# STM32H723VEH6 register map
File version: 1.0
Registers are 32-bit, access not given, reset 0x0 unless marked. A register's access mark holds for its fields unless they carry their own. Offsets are from the block's base; [hi:lo] are bit positions; {n}, {i} and the like mark numbered series.

## DCMI
Base 0x48020000
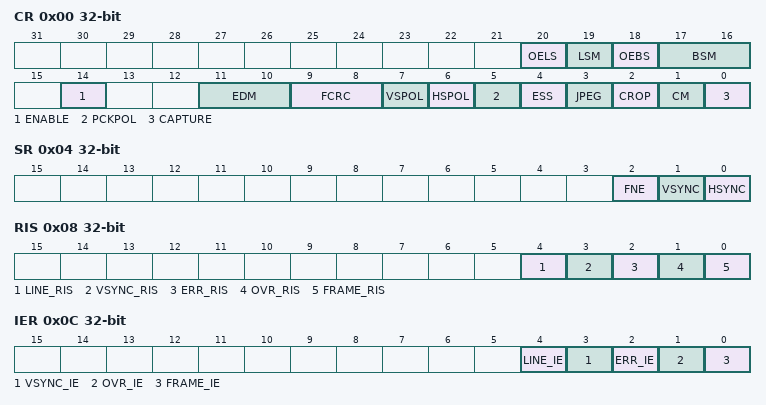
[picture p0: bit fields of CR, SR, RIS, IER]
0x00 CR
  [20] OELS, [19] LSM, [18] OEBS, [17:16] BSM, [14] ENABLE, [11:10] EDM, [9:8] FCRC, [7] VSPOL, [6] HSPOL, [5] PCKPOL, [4] ESS, [3] JPEG, [2] CROP, [1] CM, [0] CAPTURE
0x04 SR
  [2] FNE, [1] VSYNC, [0] HSYNC
0x08 RIS
  [4] LINE_RIS, [3] VSYNC_RIS, [2] ERR_RIS, [1] OVR_RIS, [0] FRAME_RIS
0x0C IER
  [4] LINE_IE, [3] VSYNC_IE, [2] ERR_IE, [1] OVR_IE, [0] FRAME_IE
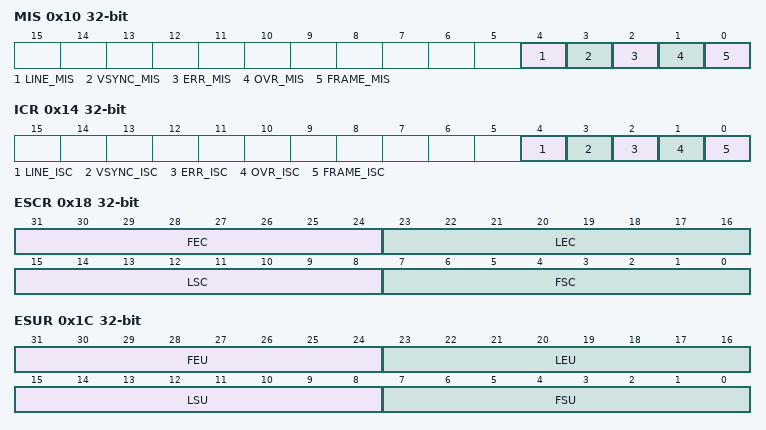
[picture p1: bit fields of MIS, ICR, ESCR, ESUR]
0x10 MIS
  [4] LINE_MIS, [3] VSYNC_MIS, [2] ERR_MIS, [1] OVR_MIS, [0] FRAME_MIS
0x14 ICR
  [4] LINE_ISC, [3] VSYNC_ISC, [2] ERR_ISC, [1] OVR_ISC, [0] FRAME_ISC
0x18 ESCR
  [31:24] FEC, [23:16] LEC, [15:8] LSC, [7:0] FSC
0x1C ESUR
  [31:24] FEU, [23:16] LEU, [15:8] LSU, [7:0] FSU
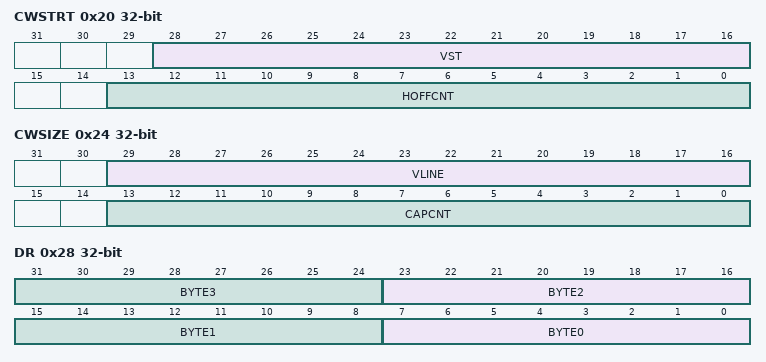
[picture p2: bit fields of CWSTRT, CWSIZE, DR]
0x20 CWSTRT
  [28:16] VST, [13:0] HOFFCNT
0x24 CWSIZE
  [29:16] VLINE, [13:0] CAPCNT
0x28 DR
  [8n+7:8n] BYTE{n} (n=0..3)

## PSSI
Base 0x48020400
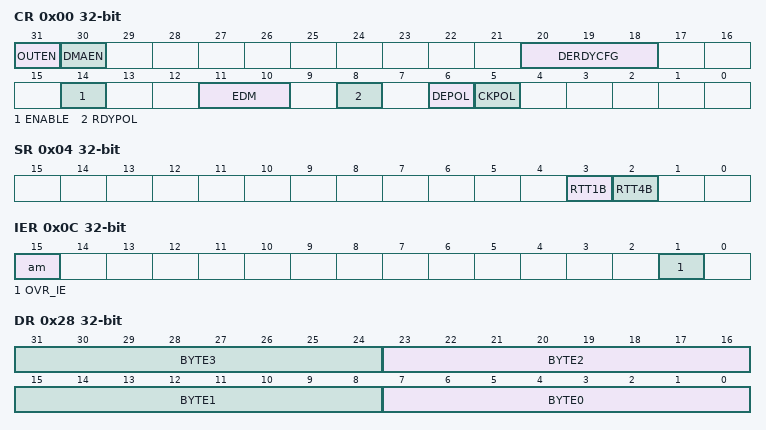
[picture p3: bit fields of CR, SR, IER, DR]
0x00 CR
  [31] OUTEN, [30] DMAEN, [20:18] DERDYCFG, [14] ENABLE, [11:10] EDM, [8] RDYPOL, [6] DEPOL, [5] CKPOL
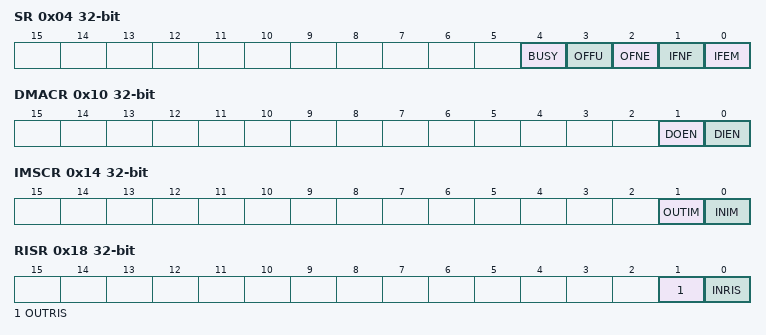
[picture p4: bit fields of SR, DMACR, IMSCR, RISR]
0x04 SR
  [3] RTT1B, [2] RTT4B
0x08 RIS
  [1] OVR_RIS
0x0C IER
  [15] am, [1] OVR_IE
0x10 MIS
  [1] OVR_MIS
0x14 ICR
  [1] OVR_ISC
0x28 DR
  [8n+7:8n] BYTE{n} (n=0..3)

## CRYPTO
Base 0x48021000
0x00 CR
  [23:20] NPBLB, [17:16] GCM_CCMPH, [15] CRYPEN, [14] FFLUSH, [9:8] KEYSIZE, [7:6] DATATYPE, [19:3] ALGOMODE, [2] ALGODIR
0x04 SR
  [4] BUSY, [3] OFFU, [2] OFNE, [1] IFNF, [0] IFEM
0x08 DIN
  [31:0] DATAIN
0x0C DOUT
  [31:0] DATAOUT
0x10 DMACR
  [1] DOEN, [0] DIEN
0x14 IMSCR
  [1] OUTIM, [0] INIM
0x18 RISR
  [1] OUTRIS, [0] INRIS
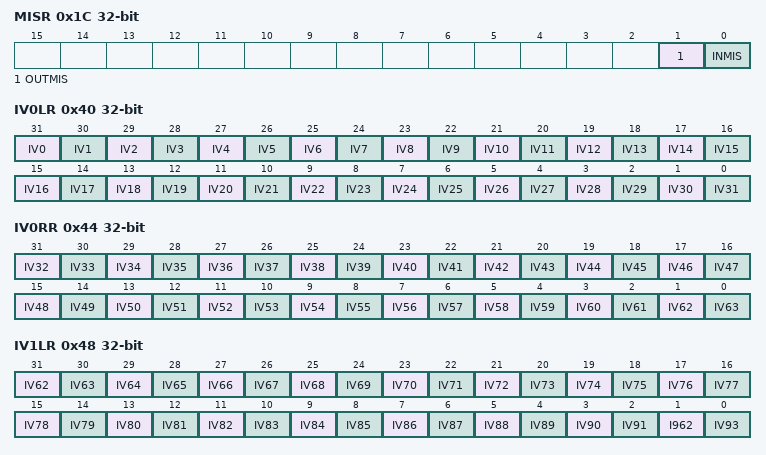
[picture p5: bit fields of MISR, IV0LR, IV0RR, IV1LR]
0x1C MISR
  [1] OUTMIS, [0] INMIS
0x20 K0LR
  [31:0] K
0x24 K0RR
  [31:0] K
0x38 K3LR
  [31:0] K
0x3C K3RR
  [31:0] K
0x40 IV0LR
  [31-n] IV{n} (n=0..31)
0x44 IV0RR
  [63-n] IV{n} (n=32..63)
0x48 IV1LR
  [93-n] IV{n} (n=62..91), [1] I962, [0] IV93
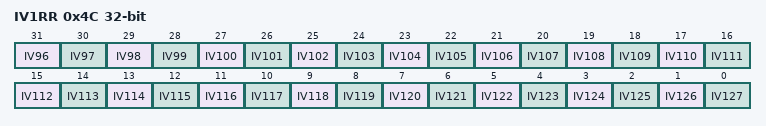
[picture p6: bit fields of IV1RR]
0x4C IV1RR
  [127-n] IV{n} (n=96..127)
{0x50+4i} CSGCMCCM{i}R (i=0..7)
  [31:0] CSGCMCCM{i}
{0x70+4i} CSGCM{i}R (i=0..7)
  [31:0] CSGCM{i}

## HASH
Base 0x48021400
0x00 CR
  [16] LKEY, [13] MDMAT, [12] DINNE, [11:8] NBW, [18:7] ALGO, [6] MODE, [5:4] DATATYPE, [3] DMAE, [2] INIT
0x04 DIN
  [31:0] DATAIN
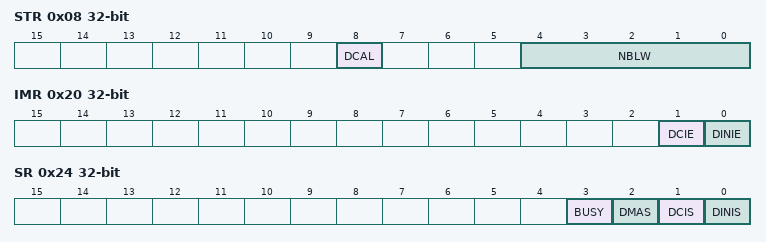
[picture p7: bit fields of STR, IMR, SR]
0x08 STR
  [8] DCAL, [4:0] NBLW
{0xC+4i} HRA{i} (i=0..4)
  [31:0] H{i}
0x20 IMR
  [1] DCIE, [0] DINIE
0x24 SR
  [3] BUSY, [2] DMAS, [1] DCIS, [0] DINIS
{0xF8+4i} CSR{i} (i=0..53)
  [31:0] CSx
{0x310+4i} HR{i} (i=0..7)
  [31:0] H{i}

## RNG
Base 0x48021800
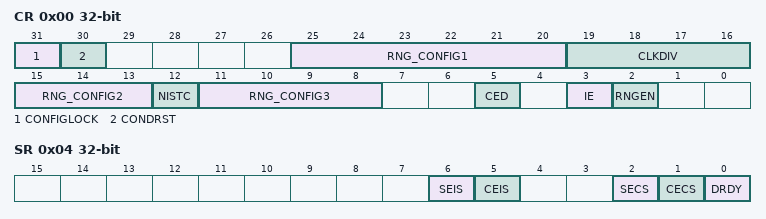
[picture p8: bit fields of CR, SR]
0x00 CR
  [31] CONFIGLOCK, [30] CONDRST, [25:20] RNG_CONFIG1, [19:16] CLKDIV, [15:13] RNG_CONFIG2, [12] NISTC, [11:8] RNG_CONFIG3, [5] CED, [3] IE, [2] RNGEN
0x04 SR
  [6] SEIS, [5] CEIS, [2] SECS, [1] CECS, [0] DRDY
0x08 DR
  [31:0] RNDATA
0x10 HTCR
  [31:0] HTCFG

## SDMMC2
Base 0x48022400
Same registers: SDMMC1 0x52007000
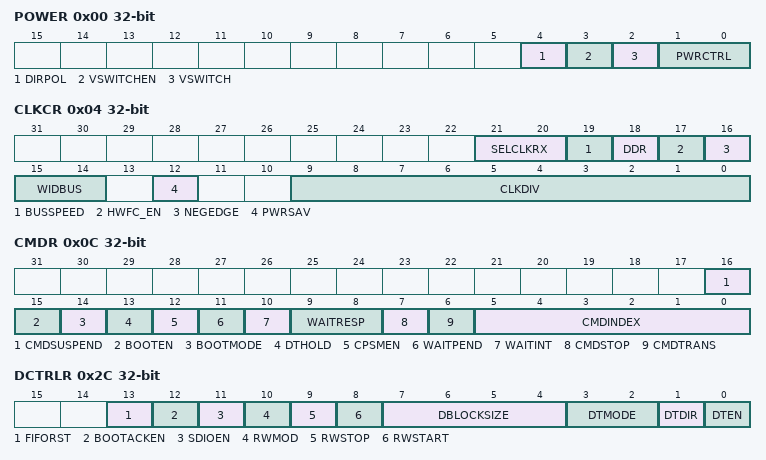
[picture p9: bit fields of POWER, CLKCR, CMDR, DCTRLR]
0x00 POWER
  [4] DIRPOL, [3] VSWITCHEN, [2] VSWITCH, [1:0] PWRCTRL
0x04 CLKCR
  [21:20] SELCLKRX, [19] BUSSPEED, [18] DDR, [17] HWFC_EN, [16] NEGEDGE, [15:14] WIDBUS, [12] PWRSAV, [9:0] CLKDIV
0x08 ARGR
  [31:0] CMDARG
0x0C CMDR
  [16] CMDSUSPEND, [15] BOOTEN, [14] BOOTMODE, [13] DTHOLD, [12] CPSMEN, [11] WAITPEND, [10] WAITINT, [9:8] WAITRESP, [7] CMDSTOP, [6] CMDTRANS, [5:0] CMDINDEX
0x10 RESPCMDR
  [5:0] RESPCMD
{0x10+4i} RESP{i}R (i=1..4)
  [31:0] CARDSTATUS
0x24 DTIMER
  [31:0] DATATIME
0x28 DLENR
  [24:0] DATALENGTH
0x2C DCTRLR
  [13] FIFORST, [12] BOOTACKEN, [11] SDIOEN, [10] RWMOD, [9] RWSTOP, [8] RWSTART, [7:4] DBLOCKSIZE, [3:2] DTMODE, [1] DTDIR, [0] DTEN
0x30 DCNTR
  [24:0] DATACOUNT
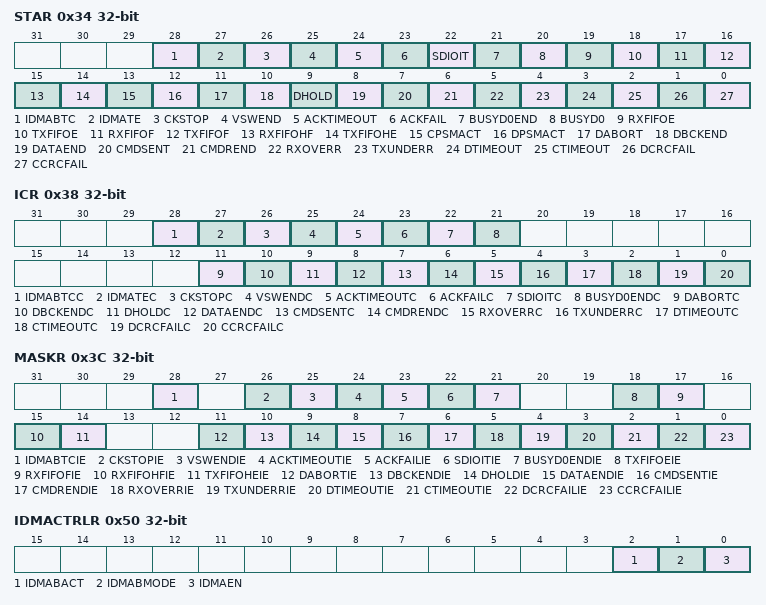
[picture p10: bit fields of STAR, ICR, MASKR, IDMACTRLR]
0x34 STAR
  [28] IDMABTC, [27] IDMATE, [26] CKSTOP, [25] VSWEND, [24] ACKTIMEOUT, [23] ACKFAIL, [22] SDIOIT, [21] BUSYD0END, [20] BUSYD0, [19] RXFIFOE, [18] TXFIFOE, [17] RXFIFOF, [16] TXFIFOF, [15] RXFIFOHF, [14] TXFIFOHE, [13] CPSMACT, [12] DPSMACT, [11] DABORT, [10] DBCKEND, [9] DHOLD, [8] DATAEND, [7] CMDSENT, [6] CMDREND, [5] RXOVERR, [4] TXUNDERR, [3] DTIMEOUT, [2] CTIMEOUT, [1] DCRCFAIL, [0] CCRCFAIL
0x38 ICR
  [28] IDMABTCC, [27] IDMATEC, [26] CKSTOPC, [25] VSWENDC, [24] ACKTIMEOUTC, [23] ACKFAILC, [22] SDIOITC, [21] BUSYD0ENDC, [11] DABORTC, [10] DBCKENDC, [9] DHOLDC, [8] DATAENDC, [7] CMDSENTC, [6] CMDRENDC, [5] RXOVERRC, [4] TXUNDERRC, [3] DTIMEOUTC, [2] CTIMEOUTC, [1] DCRCFAILC, [0] CCRCFAILC
0x3C MASKR
  [28] IDMABTCIE, [26] CKSTOPIE, [25] VSWENDIE, [24] ACKTIMEOUTIE, [23] ACKFAILIE, [22] SDIOITIE, [21] BUSYD0ENDIE, [18] TXFIFOEIE, [17] RXFIFOFIE, [15] RXFIFOHFIE, [14] TXFIFOHEIE, [11] DABORTIE, [10] DBCKENDIE, [9] DHOLDIE, [8] DATAENDIE, [7] CMDSENTIE, [6] CMDRENDIE, [5] RXOVERRIE, [4] TXUNDERRIE, [3] DTIMEOUTIE, [2] CTIMEOUTIE, [1] DCRCFAILIE, [0] CCRCFAILIE
0x40 ACKTIMER
  [24:0] ACKTIME
0x50 IDMACTRLR
  [2] IDMABACT, [1] IDMABMODE, [0] IDMAEN
0x54 IDMABSIZER
  [12:5] IDMABNDT
0x58 IDMABASE0R
  [31:0] IDMABASE0
0x5C IDMABASE1R
  [31:0] IDMABASE1
0x80 FIFOR.0
  [31:0] FIFODATA
0x84 FIFOR.1
  [31:0] FIFODATA
0x88 FIFOR.2
  [31:0] FIFODATA
0x8C FIFOR.3
  [31:0] FIFODATA
0x90 FIFOR.4
  [31:0] FIFODATA
0x94 FIFOR.5
  [31:0] FIFODATA
0x98 FIFOR.6
  [31:0] FIFODATA
0x9C FIFOR.7
  [31:0] FIFODATA
0xA0 FIFOR.8
  [31:0] FIFODATA
0xA4 FIFOR.9
  [31:0] FIFODATA
0xA8 FIFOR.10
  [31:0] FIFODATA
0xAC FIFOR.11
  [31:0] FIFODATA
0xB0 FIFOR.12
  [31:0] FIFODATA
0xB4 FIFOR.13
  [31:0] FIFODATA
0xB8 FIFOR.14
  [31:0] FIFODATA
0xBC FIFOR.15
  [31:0] FIFODATA
